AUTOSAR XML (schema 321)
package /ComponentType
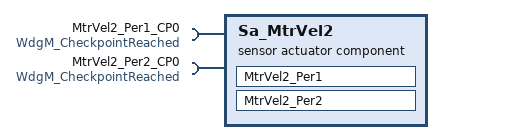
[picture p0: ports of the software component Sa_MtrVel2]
  sensor actuator software component type Sa_MtrVel2
    require port MtrVel2_Per1_CP0: client-com-spec=CheckpointReached, required-interface=WdgM_CheckpointReached
    require port MtrVel2_Per2_CP0: client-com-spec=CheckpointReached, required-interface=WdgM_CheckpointReached
  internal behavior Sa_MtrVel2_InternalBehavior: component=Sa_MtrVel2
    port-api-options:
      enable-take-address=false, indirect-api=false, port=MtrVel2_Per1_CP0
      enable-take-address=false, indirect-api=false, port=MtrVel2_Per2_CP0
    runnable MtrVel2_Per1
      sync call SC_MtrVel2_Per1_CP0_CheckpointReached: operation=MtrVel2_Per1_CP0.CheckpointReached, timeout=0
    runnable MtrVel2_Per2
      sync call SC_MtrVel2_Per2_CP0_CheckpointReached: operation=MtrVel2_Per2_CP0.CheckpointReached, timeout=0
  swc implementation Sa_MtrVel2_Implementation: behavior=Sa_MtrVel2_InternalBehavior
    code-descriptors:
      code Code: type=SRC
package /PortInterface
  client server interface WdgM_CheckpointReached: is-service=true
    operation CheckpointReached: possible-error=E_NOT_OK  # Indicates to the Watchdog Manager that a Checkpoint within a Supervised Entity has been reached.
    error E_NOT_OK: error-code=1
